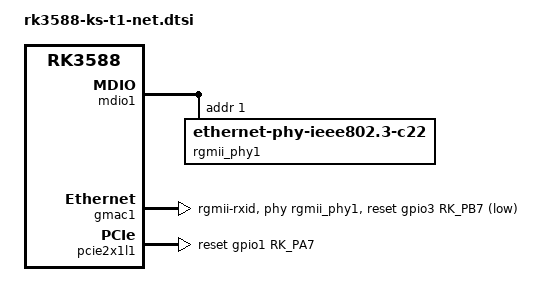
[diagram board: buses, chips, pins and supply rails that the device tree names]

/ {
    /*vcc3v3_pcie20: vcc3v3-pcie20 {
		compatible = "regulator-fixed";
		regulator-name = "vcc3v3_pcie20";
		regulator-min-microvolt = <3300000>;
		regulator-max-microvolt = <3300000>;
		enable-active-high;
		startup-delay-us = <5000>;
		vin-supply = <&vcc12v_dcin>;
	};*/
};

&mdio1 {
	rgmii_phy1: phy@1 {
		compatible = "ethernet-phy-ieee802.3-c22";
		reg = <0x1>;
		clocks = <&cru REFCLKO25M_ETH1_OUT>;
	};
};

&gmac1 {
	/* Use rgmii-rxid mode to disable rx delay inside Soc */
	phy-mode = "rgmii-rxid";
	clock_in_out = "output";

	snps,reset-gpio = <&gpio3 RK_PB7 GPIO_ACTIVE_LOW>;
	snps,reset-active-low;
	/* Reset time is 20ms, 100ms for rtl8211f */
	snps,reset-delays-us = <0 20000 100000>;

	pinctrl-names = "default";
	pinctrl-0 = <&gmac1_miim
		     &gmac1_tx_bus2
		     &gmac1_rx_bus2
		     &gmac1_rgmii_clk
		     &gmac1_rgmii_bus
			 &eth1_pins>;

	tx_delay = <0x44>;
	//rx_delay = <0x4f>;

	phy-handle = <&rgmii_phy1>;
	status = "okay";
};

&pcie2x1l1 {
	reset-gpios = <&gpio1 RK_PA7 GPIO_ACTIVE_HIGH>;
	//pinctrl-names = "default";
	//pinctrl-0 = <&rtl8111_isolate>;
	//vpcie3v3-supply = <&vcc3v3_pcie20>;
	rockchip,skip-scan-in-resume;
	status = "okay";
};

&pinctrl {
	rtl8111_isolate: rtl8111_isolate {
		rockchip,pins = <1 RK_PA7 RK_FUNC_GPIO &pcfg_pull_up>;
	};
};
/* GPIO3_B7 is gmac1's PHY reset line (snps,reset-gpio above). The EVB
 * work_led inherited from rk3588-evb.dtsi claims the same pin; stmmac
 * releases the reset GPIO after its probe-time pulse (stmmac_mdio_reset
 * devm_gpiod_put), so leds-gpio wins the pin and holds/bounces the
 * RTL8211F in hardware reset -> "Failed to reset the dma" on every open
 * (heartbeat trigger makes it intermittent). KS_T1 has no work LED
 * fitted; disable the node.
 */
&leds {
	status = "disabled";
};
